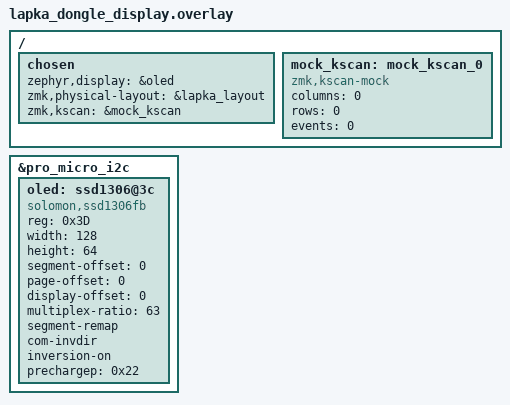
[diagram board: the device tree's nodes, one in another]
#include <dt-bindings/zmk/matrix_transform.h>
#include "lapka-layouts.dtsi"
#include "lapka-transform.dtsi"

/ {
    chosen {
        zephyr,display = &oled;
        zmk,physical-layout = &lapka_layout;
        zmk,kscan = &mock_kscan;
    };

    mock_kscan: mock_kscan_0 {
        compatible = "zmk,kscan-mock";
        columns = <0>;
        rows = <0>;
        events = <0>;
    };
};

// 128x64 OLED
&pro_micro_i2c {
    status = "okay";

    oled: ssd1306@3c {
        compatible = "solomon,ssd1306fb";
        reg = <0x3D>;
        width = <128>;
        height = <64>;
        segment-offset = <0>;
        page-offset = <0>;
        display-offset = <0>;
        multiplex-ratio = <63>;
        segment-remap;
        com-invdir;
        inversion-on;
        prechargep = <0x22>;
    };
};
